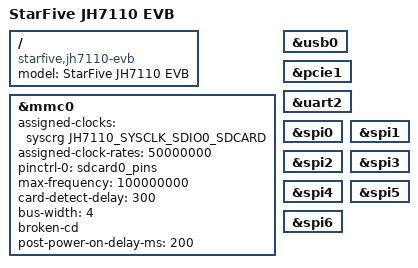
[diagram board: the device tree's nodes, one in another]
// SPDX-License-Identifier: GPL-2.0 OR MIT
/*
 * Copyright (C) 2022 StarFive Technology Co., Ltd.
 */

/dts-v1/;
#include "jh7110-evb.dtsi"

/ {
	model = "StarFive JH7110 EVB";
	compatible = "starfive,jh7110-evb", "starfive,jh7110";
};

&mmc0 {
	assigned-clocks = <&syscrg JH7110_SYSCLK_SDIO0_SDCARD>;
	assigned-clock-rates = <50000000>;
	pinctrl-names = "default";
	pinctrl-0 = <&sdcard0_pins>;
	max-frequency = <100000000>;
	card-detect-delay = <300>;
	bus-width = <4>;
	broken-cd;
	post-power-on-delay-ms = <200>;
	status = "okay";
};

&usb0 {
	status = "okay";
};

&pcie1 {
	status = "okay";
};

&uart2 {
	status = "okay";
};

&spi0 {
	status = "okay";
};

&spi1 {
	status = "okay";
};

&spi2 {
	status = "okay";
};

&spi3 {
	status = "okay";
};

&spi4 {
	status = "okay";
};

&spi5 {
	status = "okay";
};

&spi6 {
	status = "okay";
};
